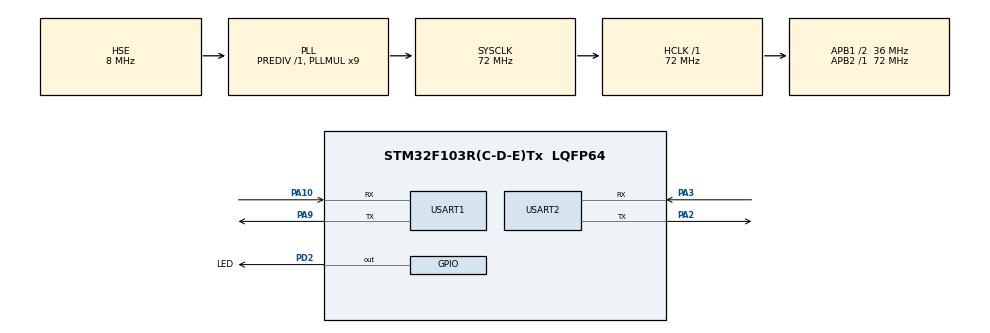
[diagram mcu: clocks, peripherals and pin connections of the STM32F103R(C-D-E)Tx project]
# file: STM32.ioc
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Dma.Request0=USART2_RX
Dma.USART2_RX.0.Direction=DMA_PERIPH_TO_MEMORY
Dma.USART2_RX.0.Instance=DMA1_Channel6
Dma.USART2_RX.0.MemDataAlignment=DMA_MDATAALIGN_BYTE
Dma.USART2_RX.0.MemInc=DMA_MINC_ENABLE
Dma.USART2_RX.0.Mode=DMA_NORMAL
Dma.USART2_RX.0.PeriphDataAlignment=DMA_PDATAALIGN_BYTE
Dma.USART2_RX.0.PeriphInc=DMA_PINC_DISABLE
Dma.USART2_RX.0.Priority=DMA_PRIORITY_LOW
Mcu.Family=STM32F1
Mcu.Name=STM32F103R(C-D-E)Tx
Mcu.Package=LQFP64
NVIC.DMA1_Channel6_IRQn=true\:0\:0\:false\:false\:true\:false\:true\:true
NVIC.PriorityGroup=NVIC_PRIORITYGROUP_4
NVIC.USART2_IRQn=true\:0\:0\:false\:false\:true\:true\:true\:true
PA10.Mode=Asynchronous
PA10.Signal=USART1_RX
PA13.Mode=Serial_Wire
PA13.Signal=SYS_JTMS-SWDIO
PA14.Mode=Serial_Wire
PA14.Signal=SYS_JTCK-SWCLK
PA2.Mode=Asynchronous
PA2.Signal=USART2_TX
PA3.Mode=Asynchronous
PA3.Signal=USART2_RX
PA9.Mode=Asynchronous
PA9.Signal=USART1_TX
PD0-OSC_IN.Mode=HSE-External-Oscillator
PD0-OSC_IN.Signal=RCC_OSC_IN
PD1-OSC_OUT.Mode=HSE-External-Oscillator
PD1-OSC_OUT.Signal=RCC_OSC_OUT
PD2.GPIO_Label=LED
PD2.Signal=GPIO_Output
ProjectManager.HeapSize=0x200
ProjectManager.StackSize=0x400
ProjectManager.TargetToolchain=Makefile
RCC.AHBFreq_Value=72000000
RCC.APB1CLKDivider=RCC_HCLK_DIV2
RCC.APB1Freq_Value=36000000
RCC.APB1TimFreq_Value=72000000
RCC.APB2Freq_Value=72000000
RCC.APB2TimFreq_Value=72000000
RCC.HCLKFreq_Value=72000000
RCC.PLLMUL=RCC_PLL_MUL9
RCC.PLLSourceVirtual=RCC_PLLSOURCE_HSE
RCC.SYSCLKFreq_VALUE=72000000
RCC.SYSCLKSource=RCC_SYSCLKSOURCE_PLLCLK
RCC.USBFreq_Value=72000000
USART1.VirtualMode=VM_ASYNC
USART2.VirtualMode=VM_ASYNC
board=custom

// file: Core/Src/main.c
/* USER CODE BEGIN Header */
/**
  ******************************************************************************
  * @file           : main.c
  * @brief          : Main program body
  ******************************************************************************
  * @attention
  *
  * Copyright (c) 2023 STMicroelectronics.
  * All rights reserved.
  *
  * This software is licensed under terms that can be found in the LICENSE file
  * in the root directory of this software component.
  * If no LICENSE file comes with this software, it is provided AS-IS.
  *
  ******************************************************************************
  */
/* USER CODE END Header */
#include "main.h"
#include "dma.h"
#include "usart.h"
#include "gpio.h"
#include "JY62.h"

void SystemClock_Config(void);

/* USER CODE BEGIN 0 */
void jy62_Init(UART_HandleTypeDef* huart);
/* USER CODE END 0 */

int main(void)
{

  /* MCU Configuration--------------------------------------------------------*/

  /* Reset of all peripherals, Initializes the Flash interface and the Systick. */
  HAL_Init();

  /* Configure the system clock */
  SystemClock_Config();

  /* Initialize all configured peripherals */
  MX_GPIO_Init();
  MX_DMA_Init();
  MX_USART2_UART_Init();
  MX_USART1_UART_Init();

  /* Infinite loop */
  /* USER CODE BEGIN WHILE */
  SetBaud(115200);
  SetHorizontal();
  InitAngle();
  Calibrate();
  SleepOrAwake();
  HAL_Delay(1000);
  jy62_Init(&huart2);
  while (1)
  {
      /* USER CODE END WHILE */
      /* USER CODE BEGIN 3 */
      float roll = GetRoll();
      float pitch = GetPitch();
      float yaw = GetYaw();
      u1_printf("ROW: %f, PITCH:%f, YAW:%f\r\n", roll, pitch, yaw);
  }
  /* USER CODE END 3 */
}

void SystemClock_Config(void)
{
  RCC_OscInitTypeDef RCC_OscInitStruct = {0};
  RCC_ClkInitTypeDef RCC_ClkInitStruct = {0};

  /** Initializes the RCC Oscillators according to the specified parameters
  * in the RCC_OscInitTypeDef structure.
  */
  RCC_OscInitStruct.OscillatorType = RCC_OSCILLATORTYPE_HSE;
  RCC_OscInitStruct.HSEState = RCC_HSE_ON;
  RCC_OscInitStruct.HSEPredivValue = RCC_HSE_PREDIV_DIV1;
  RCC_OscInitStruct.HSIState = RCC_HSI_ON;
  RCC_OscInitStruct.PLL.PLLState = RCC_PLL_ON;
  RCC_OscInitStruct.PLL.PLLSource = RCC_PLLSOURCE_HSE;
  RCC_OscInitStruct.PLL.PLLMUL = RCC_PLL_MUL9;
  if (HAL_RCC_OscConfig(&RCC_OscInitStruct) != HAL_OK)
  {
    Error_Handler();
  }

  /** Initializes the CPU, AHB and APB buses clocks
  */
  RCC_ClkInitStruct.ClockType = RCC_CLOCKTYPE_HCLK|RCC_CLOCKTYPE_SYSCLK
                              |RCC_CLOCKTYPE_PCLK1|RCC_CLOCKTYPE_PCLK2;
  RCC_ClkInitStruct.SYSCLKSource = RCC_SYSCLKSOURCE_PLLCLK;
  RCC_ClkInitStruct.AHBCLKDivider = RCC_SYSCLK_DIV1;
  RCC_ClkInitStruct.APB1CLKDivider = RCC_HCLK_DIV2;
  RCC_ClkInitStruct.APB2CLKDivider = RCC_HCLK_DIV1;

  if (HAL_RCC_ClockConfig(&RCC_ClkInitStruct, FLASH_LATENCY_2) != HAL_OK)
  {
    Error_Handler();
  }
}

void Error_Handler(void)
{
  __disable_irq();
  while (1)
  {
  }
}
